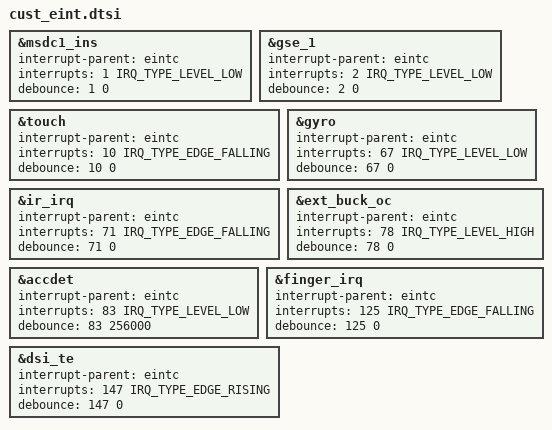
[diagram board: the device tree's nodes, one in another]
/*
 * Generated by MTK SP Drv_CodeGen Version 03.13.6	for MT6735M. Copyright MediaTek Inc. (C) 2013.
 * Fri Feb 22 18:03:04 2019
 * Do Not Modify the File.
 */

#include <dt-bindings/interrupt-controller/irq.h>
#include <dt-bindings/interrupt-controller/arm-gic.h>

/*************************
 * EINT DTSI File
*************************/

&msdc1_ins {
	interrupt-parent = <&eintc>;
	interrupts = <1 IRQ_TYPE_LEVEL_LOW>;
	debounce = <1 0>;
	status = "okay";
};
&gse_1 {
	interrupt-parent = <&eintc>;
	interrupts = <2 IRQ_TYPE_LEVEL_LOW>;
	debounce = <2 0>;
	status = "okay";
};
&touch {
	interrupt-parent = <&eintc>;
	interrupts = <10 IRQ_TYPE_EDGE_FALLING>;
	debounce = <10 0>;
	status = "okay";
};
&gyro {
	interrupt-parent = <&eintc>;
	interrupts = <67 IRQ_TYPE_LEVEL_LOW>;
	debounce = <67 0>;
	status = "okay";
};
&ir_irq {
	interrupt-parent = <&eintc>;
	interrupts = <71 IRQ_TYPE_EDGE_FALLING>;
	debounce = <71 0>;
	status = "okay";
};
&ext_buck_oc {
	interrupt-parent = <&eintc>;
	interrupts = <78 IRQ_TYPE_LEVEL_HIGH>;
	debounce = <78 0>;
	status = "okay";
};
&accdet {
	interrupt-parent = <&eintc>;
	interrupts = <83 IRQ_TYPE_LEVEL_LOW>;
	debounce = <83 256000>;
	status = "okay";
};
&finger_irq {
	interrupt-parent = <&eintc>;
	interrupts = <125 IRQ_TYPE_EDGE_FALLING>;
	debounce = <125 0>;
	status = "okay";
};
&dsi_te {
	interrupt-parent = <&eintc>;
	interrupts = <147 IRQ_TYPE_EDGE_RISING>;
	debounce = <147 0>;
	status = "okay";
};
